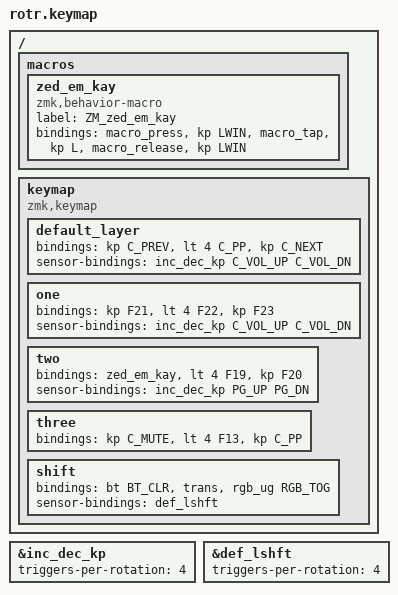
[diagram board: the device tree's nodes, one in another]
#include <behaviors.dtsi>
#include <dt-bindings/zmk/keys.h>
#include <dt-bindings/zmk/rgb.h>
#include <dt-bindings/zmk/bt.h>

/ {
    macros {
        zed_em_kay: zed_em_kay {
            label = "ZM_zed_em_kay";
            compatible = "zmk,behavior-macro";
            #binding-cells = <0>;
            bindings
                = <&macro_press &kp LWIN>
                , <&macro_tap &kp L>
                , <&macro_release &kp LWIN>
                ;
        };
    };
};

&inc_dec_kp {
	triggers-per-rotation = <4>;
};
&def_lshft {
	triggers-per-rotation = <4>;
};

/ {
	keymap {
		compatible = "zmk,keymap";

		default_layer {
 			//PREV | PLAY/PAUSE | NEXT
			bindings = <&kp C_PREV &lt 4 C_PP &kp C_NEXT>;
			sensor-bindings = <&inc_dec_kp C_VOL_UP C_VOL_DN>;
		};
		one {
			//DISC DEAFEN | DISC MUTE | DISC Stream
			bindings = <&kp F21 &lt 4 F22 &kp F23>;
			sensor-bindings = <&inc_dec_kp C_VOL_UP C_VOL_DN>;
		};
		two {
			//SLEEP | LOCK | F22
			bindings = <&zed_em_kay &lt 4 F19 &kp F20>;
			sensor-bindings = <&inc_dec_kp PG_UP PG_DN>;
		};
		three {
			//PREV | PLAY/PAUSE | NEXT
			bindings = <&kp C_MUTE &lt 4 F13 &kp C_PP>;
		};
		shift {
			//PREV | PLAY/PAUSE | NEXT
			bindings = <&bt BT_CLR &trans &rgb_ug RGB_TOG>;
			sensor-bindings = <&def_lshft>;
		};
	};
};
